CM_ "IMPORT _hyundai_can_common.dbc";

BO_ 1046 AX1_LDA_BUTTON: 8 XXX
 SG_ LDA_BTN : 58|1@1+ (1,0) [0|1] "" XXX

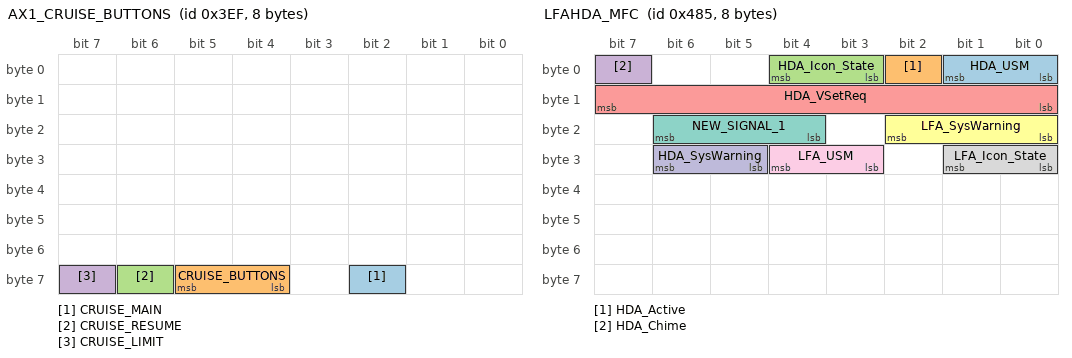
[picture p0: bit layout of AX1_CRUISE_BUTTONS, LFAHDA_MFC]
BO_ 1007 AX1_CRUISE_BUTTONS: 8 XXX
 SG_ CRUISE_MAIN : 58|1@1+ (1,0) [0|1] "" XXX
 SG_ CRUISE_BUTTONS : 60|2@1+ (1,0) [0|3] "" XXX
 SG_ CRUISE_RESUME : 62|1@1+ (1,0) [0|1] "" XXX
 SG_ CRUISE_LIMIT : 63|1@1+ (1,0) [0|1] "" XXX

BO_ 1157 LFAHDA_MFC: 8 XXX
 SG_ HDA_USM : 0|2@1+ (1,0) [0|3] "" XXX
 SG_ HDA_Active : 2|1@1+ (1,0) [0|1] "" XXX
 SG_ HDA_Icon_State : 3|2@1+ (1,0) [0|3] "" XXX
 SG_ HDA_Chime : 7|1@1+ (1,0) [0|1] "" XXX
 SG_ HDA_VSetReq : 8|8@1+ (1,0) [0|255] "km/h" XXX
 SG_ LFA_SysWarning : 16|3@1+ (1,0) [0|7] "" XXX
 SG_ NEW_SIGNAL_1 : 20|3@1+ (1,0) [0|7] "" XXX
 SG_ LFA_Icon_State : 24|2@1+ (1,0) [0|3] "" XXX
 SG_ LFA_USM : 27|2@1+ (1,0) [0|3] "" XXX
 SG_ HDA_SysWarning : 29|2@1+ (1,0) [0|3] "" XXX

CM_ SG_ 1007 CRUISE_BUTTONS "Steering wheel +/- toggle, same encoding as CLU11 CF_Clu_CruiseSwState. 3 (gap) has not been observed on AX1EV yet";
CM_ SG_ 1007 CRUISE_RESUME "Combined pause/resume button. Cancels SCC while engaged, resumes otherwise";
CM_ SG_ 1157 HDA_Active "Unused on AX1EV, HDA state is reported only via HDA_Icon_State";
CM_ SG_ 1157 HDA_VSetReq "Unused on AX1EV, always 0 even while HDA is active";

VAL_ 1007 CRUISE_BUTTONS 0 "none" 1 "res_accel" 2 "set_decel" 3 "gap_dist";
